# ATUC64D3 device description
Architecture: AVR32_UC3; Family: AVR UC3
Registers are 32-bit, read-write, reset 0x0 unless marked. A register's access mark holds for its fields unless they carry their own. Offsets are from the block's base; [hi:lo] are bit positions; 'fields as' and 'values as' point back to an identical list.

## TWIM — Two-wire Master Interface
Instances: TWIM 0xffff4000
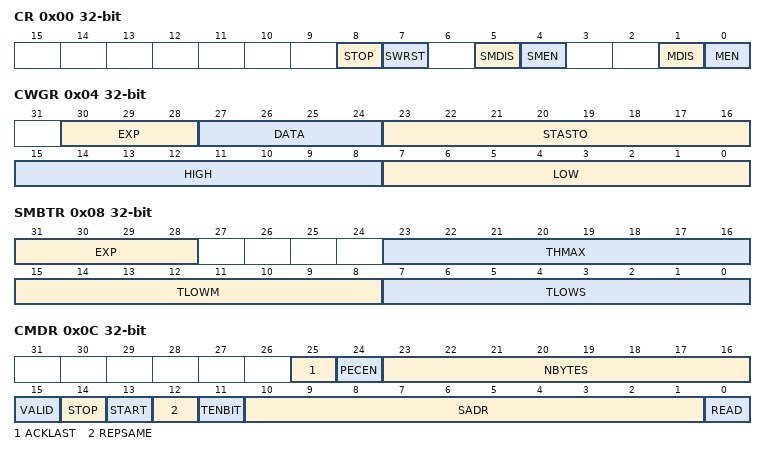
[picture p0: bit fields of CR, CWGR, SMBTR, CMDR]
0x00 CR wo — Control
  [8] STOP — Stop the current transfer
  [7] SWRST — Software Reset
  [5] SMDIS — SMBus Disable
  [4] SMEN — SMBus Enable
  [1] MDIS — Master Disable
  [0] MEN — Master Enable
0x04 CWGR — Clock Waveform Generator
  [30:28] EXP — Clock Prescaler
  [27:24] DATA — Data Setup and Hold Cycles
  [23:16] STASTO — START and STOP Cycles
  [15:8] HIGH — Clock High Cycles
  [7:0] LOW — Clock Low Cycles
0x08 SMBTR — SMBus Timing
  [31:28] EXP — SMBus Timeout Clock prescaler
  [23:16] THMAX — Clock High maximum cycles
  [15:8] TLOWM — Master Clock stretch maximum cycles
  [7:0] TLOWS — Slave Clock stretch maximum cycles
0x0C CMDR — Command
  [25] ACKLAST — ACK Last Master RX Byte
  [24] PECEN — Packet Error Checking Enable
  [23:16] NBYTES — Number of data bytes in transfer
  [15] VALID — CMDR Valid
  [14] STOP — Send STOP condition
  [13] START — Send START condition
  [12] REPSAME — Transfer is to same address as previous address
  [11] TENBIT — Ten Bit Addressing Mode
  [10:1] SADR — Slave Address
  [0] READ — Transfer Direction
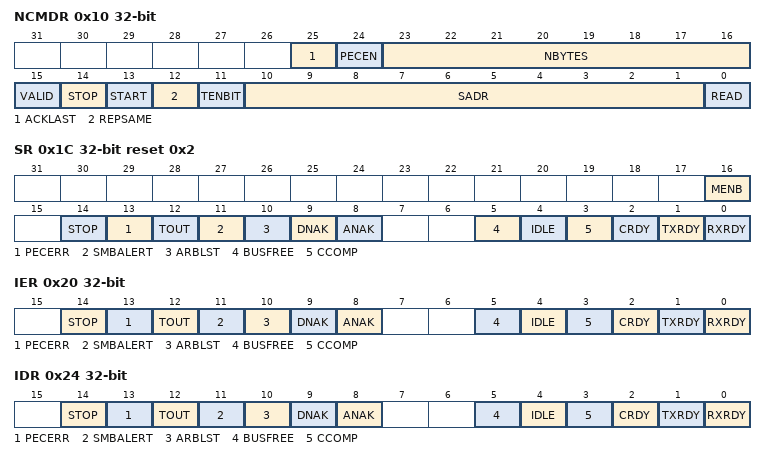
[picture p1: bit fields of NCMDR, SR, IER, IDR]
0x10 NCMDR — Next Command
  fields as CMDR
0x14 RHR ro — Receive Holding
  [7:0] RXDATA — Received Data
0x18 THR wo — Transmit Holding
  [7:0] TXDATA — Data to Transmit
0x1C SR ro reset 0x2 — Status
  [16] MENB — Master Interface Enable
  [14] STOP — Stop Request Accepted
  [13] PECERR — PEC Error
  [12] TOUT — Timeout
  [11] SMBALERT — SMBus Alert
  [10] ARBLST — Arbitration Lost
  [9] DNAK — NAK in Data Phase Received
  [8] ANAK — NAK in Address Phase Received
  [5] BUSFREE — Two-wire Bus is Free
  [4] IDLE — Master Interface is Idle
  [3] CCOMP — Command Complete
  [2] CRDY — Ready for More Commands
  [1] TXRDY — THR Data Ready
  [0] RXRDY — RHR Data Ready
0x20 IER wo — Interrupt Enable Register
  [14] STOP — Stop Request Accepted
  [13] PECERR — PEC Error
  [12] TOUT — Timeout
  [11] SMBALERT — SMBus Alert
  [10] ARBLST — Arbitration Lost
  [9] DNAK — NAK in Data Phase Received
  [8] ANAK — NAK in Address Phase Received
  [5] BUSFREE — Two-wire Bus is Free
  [4] IDLE — Master Interface is Idle
  [3] CCOMP — Command Complete
  [2] CRDY — Ready for More Commands
  [1] TXRDY — THR Data Ready
  [0] RXRDY — RHR Data Ready
0x24 IDR wo — Interrupt Disable Register
  fields as IER
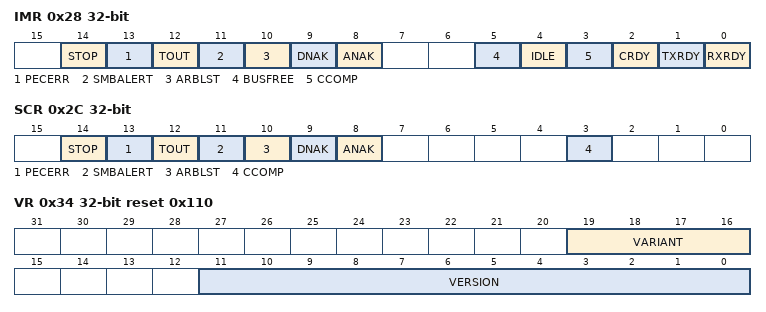
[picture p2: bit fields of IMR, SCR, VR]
0x28 IMR ro — Interrupt Mask Register
  fields as IER
0x2C SCR wo — Status Clear Register
  [14] STOP — Stop Request Accepted
  [13] PECERR — PEC Error
  [12] TOUT — Timeout
  [11] SMBALERT — SMBus Alert
  [10] ARBLST — Arbitration Lost
  [9] DNAK — NAK in Data Phase Received
  [8] ANAK — NAK in Address Phase Received
  [3] CCOMP — Command Complete
0x30 PR ro — Parameter Register
0x34 VR ro reset 0x110 — Version Register
  [19:16] VARIANT — Variant number
  [11:0] VERSION — Version number

## TWIS — Two-wire Slave Interface
Instances: TWIS 0xffff4400
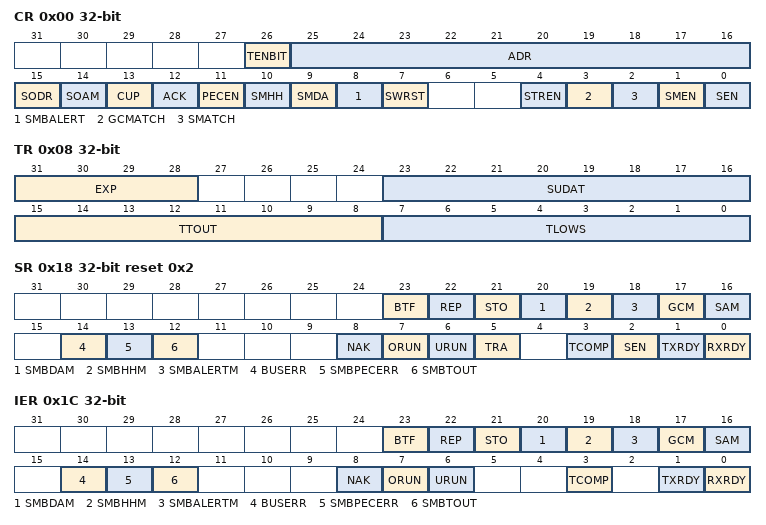
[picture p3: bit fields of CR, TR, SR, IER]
0x00 CR — Control Register
  [26] TENBIT — Ten Bit Address Match
  [25:16] ADR — Slave Address
  [15] SODR — Stretch Clock on Data Byte Reception
  [14] SOAM — Stretch Clock on Address Match
  [13] CUP — NBYTES Count Up
  [12] ACK — Slave Receiver Data Phase ACK Value
  [11] PECEN — Packet Error Checking Enable
  [10] SMHH — SMBus Host Header
  [9] SMDA — SMBus Default Address
  [8] SMBALERT — SMBus Alert
  [7] SWRST — Software Reset
  [4] STREN — Clock Stretch Enable
  [3] GCMATCH — General Call Address Match
  [2] SMATCH — Slave Address Match
  [1] SMEN — SMBus Mode Enable
  [0] SEN — Slave Enable
0x04 NBYTES
  [7:0] NBYTES — Number of Bytes to Transfer
0x08 TR — Timing Register
  [31:28] EXP — Clock Prescaler
  [23:16] SUDAT — Data Setup Cycles
  [15:8] TTOUT — SMBus Ttimeout Cycles
  [7:0] TLOWS — SMBus Tlow:sext Cycles
0x0C RHR ro — Receive Holding Register
  [7:0] RXDATA — Received Data Byte
0x10 THR wo — Transmit Holding Register
  [7:0] TXDATA — Data Byte to Transmit
0x14 PECR ro — Packet Error Check Register
  [7:0] PEC — Calculated PEC Value
0x18 SR ro reset 0x2 — Status Register
  [23] BTF — Byte Transfer Finished
  [22] REP — Repeated Start Received
  [21] STO — Stop Received
  [20] SMBDAM — SMBus Default Address Match
  [19] SMBHHM — SMBus Host Header Address Match
  [18] SMBALERTM — SMBus Alert Response Address Match
  [17] GCM — General Call Match
  [16] SAM — Slave Address Match
  [14] BUSERR — Bus Error
  [13] SMBPECERR — SMBus PEC Error
  [12] SMBTOUT — SMBus Timeout
  [8] NAK — NAK Received
  [7] ORUN — Overrun
  [6] URUN — Underrun
  [5] TRA — Transmitter Mode
  [3] TCOMP — Transmission Complete
  [2] SEN — Slave Enabled
  [1] TXRDY — TX Buffer Ready
  [0] RXRDY — RX Buffer Ready
0x1C IER wo — Interrupt Enable Register
  [23] BTF — Byte Transfer Finished
  [22] REP — Repeated Start Received
  [21] STO — Stop Received
  [20] SMBDAM — SMBus Default Address Match
  [19] SMBHHM — SMBus Host Header Address Match
  [18] SMBALERTM — SMBus Alert Response Address Match
  [17] GCM — General Call Match
  [16] SAM — Slave Address Match
  [14] BUSERR — Bus Error
  [13] SMBPECERR — SMBus PEC Error
  [12] SMBTOUT — SMBus Timeout
  [8] NAK — NAK Received
  [7] ORUN — Overrun
  [6] URUN — Underrun
  [3] TCOMP — Transmission Complete
  [1] TXRDY — TX Buffer Ready
  [0] RXRDY — RX Buffer Ready
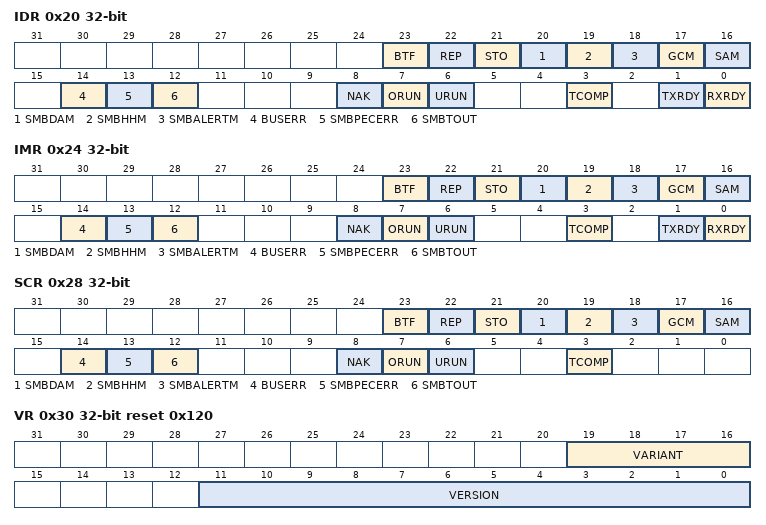
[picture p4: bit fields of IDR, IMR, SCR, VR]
0x20 IDR wo — Interrupt Disable Register
  fields as IER
0x24 IMR ro — Interrupt Mask Register
  fields as IER
0x28 SCR wo — Status Clear Register
  [23] BTF — Byte Transfer Finished
  [22] REP — Repeated Start Received
  [21] STO — Stop Received
  [20] SMBDAM — SMBus Default Address Match
  [19] SMBHHM — SMBus Host Header Address Match
  [18] SMBALERTM — SMBus Alert Response Address Match
  [17] GCM — General Call Match
  [16] SAM — Slave Address Match
  [14] BUSERR — Bus Error
  [13] SMBPECERR — SMBus PEC Error
  [12] SMBTOUT — SMBus Timeout
  [8] NAK — NAK Received
  [7] ORUN — Overrun
  [6] URUN — Underrun
  [3] TCOMP — Transmission Complete
0x2C PR ro — Parameter Register
0x30 VR ro reset 0x120 — Version Register
  [19:16] VARIANT — Variant Number
  [11:0] VERSION — Version Number

## WDT — Watchdog Timer
Instances: WDT 0xffff1c00
Parameters: WDT_KEY_CONST=85
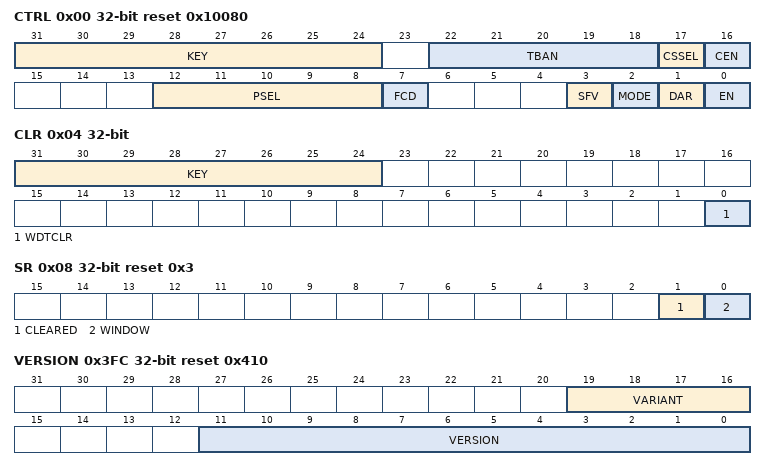
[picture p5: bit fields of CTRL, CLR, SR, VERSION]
0x00 CTRL reset 0x10080 — Control Register
  [31:24] KEY
  [22:18] TBAN — TBAN Prescale Select
  [17] CSSEL — Clock Source Selection
  [16] CEN — Clock Enable
  [12:8] PSEL — Timeout Prescale Select
  [7] FCD — WDT Fuse Calibration Done
  [3] SFV — WDT Store Final Value
  [2] MODE — WDT Mode
  [1] DAR — WDT Disable After Reset
  [0] EN — WDT Enable
0x04 CLR wo — Clear Register
  [31:24] KEY
  [0] WDTCLR — Clear WDT counter
0x08 SR ro reset 0x3 — Status Register
  [1] CLEARED — WDT cleared
  [0] WINDOW — WDT in window
0x3FC VERSION ro reset 0x410
  [19:16] VARIANT — Variant number
  [11:0] VERSION — Version number
